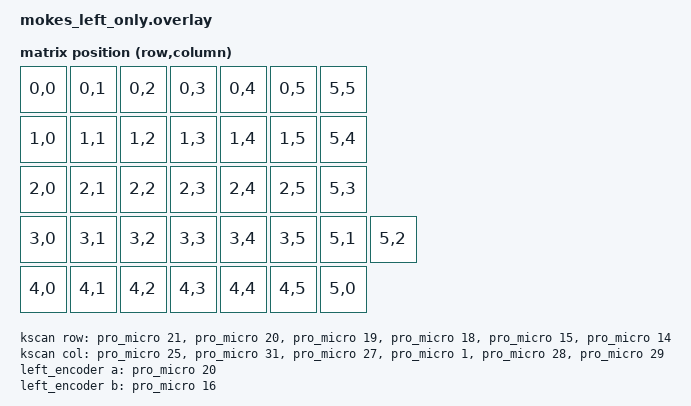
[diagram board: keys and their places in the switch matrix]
// This file was generated from a template. Edit it to match your keyboard.
// See https://zmk.dev/docs/development/hardware-integration/new-shield for more
// instructions.

#include <dt-bindings/zmk/matrix_transform.h>

#include "mokes_left_only-layouts.dtsi"

/ {
    chosen {
        zmk,physical-layout = &default_layout;
    };

    kscan: kscan {
        // If the hardware does not use a switch matrix, change this to the
        // appropriate driver and update the properties below to match.
        // See https://zmk.dev/docs/config/kscan for supported key scan drivers.
        compatible = "zmk,kscan-gpio-matrix";
        // Set this to "col2row" or "row2col" to match the hardware. If using
        // "row2col", change the col-gpios to (GPIO_ACTIVE_HIGH | GPIO_PULL_DOWN)
        // and the row-gpios to GPIO_ACTIVE_HIGH.
        diode-direction = "col2row";
        wakeup-source;

        // Replace these comments with the GPIO pins in the matrix.
        // See https://zmk.dev/docs/development/hardware-integration/new-shield#shield-overlays
        row-gpios
            = <&pro_micro 21 GPIO_ACTIVE_HIGH>
            , <&pro_micro 20 GPIO_ACTIVE_HIGH>
            , <&pro_micro 19 GPIO_ACTIVE_HIGH>
            , <&pro_micro 18 GPIO_ACTIVE_HIGH>
            , <&pro_micro 15 GPIO_ACTIVE_HIGH>
            , <&pro_micro 14 GPIO_ACTIVE_HIGH>
            ;
        col-gpios
            = <&pro_micro 25 (GPIO_ACTIVE_HIGH | GPIO_PULL_DOWN)>
            , <&pro_micro 31 (GPIO_ACTIVE_HIGH | GPIO_PULL_DOWN)>
            , <&pro_micro 27 (GPIO_ACTIVE_HIGH | GPIO_PULL_DOWN)>
            , <&pro_micro 1 (GPIO_ACTIVE_HIGH | GPIO_PULL_DOWN)>
            , <&pro_micro 28 (GPIO_ACTIVE_HIGH | GPIO_PULL_DOWN)>
            , <&pro_micro 29 (GPIO_ACTIVE_HIGH | GPIO_PULL_DOWN)>
            ;
    };
    
    left_encoder: encoder_left {
        compatible = "alps,ec11";
        a-gpios = <&pro_micro 20 (GPIO_ACTIVE_HIGH | GPIO_PULL_UP)>;
        b-gpios = <&pro_micro 16 (GPIO_ACTIVE_HIGH | GPIO_PULL_UP)>;
        steps = <80>;
        status = "disabled";
    };


//Key matrix pins
//define MATRIX_ROW_PINS { F4, F5, F6, F7, B1, B3 }
//                         21, 20, 19, 18, 15, 14
//define MATRIX_COL_PINS { D4, C6, D7, E6, B4, B5 }
//                         25, 31, 27, 1,  28, 29
//Encoder pins
//define ENCODERS_PAD_A { D2 }
//define ENCODERS_PAD_B { B2 }
// RGB_DI_PIN B6
// L00, L01, L02, L03, L04, L05, L06,    
// L10, L11, L12, L13, L14, L15, L16,    
// L20, L21, L22, L23, L24, L25, L26,    
// L30, L31, L32, L33, L34, L35, L36, L37
// L40, L41, L42, L43,    L44, L45,   L46
// { L00, L01, L02, L03, L04, L05 }, \
// { L10, L11, L12, L13, L14, L15 }, \
// { L20, L21, L22, L23, L24, L25 }, \
// { L30, L31, L32, L33, L34, L35 }, \
// { L40, L41, L42, L43, L44, L45 }, \
// { L46, L36, L37, L26, L16, L06 }, \



    default_transform: default_transform {
        // See https://zmk.dev/docs/development/hardware-integration/new-shield#matrix-transform
        // for how to configure this
        compatible = "zmk,matrix-transform";
        columns = <6>;
        rows = <6>;

        map = <
            RC(0, 0) RC(0, 1) RC(0, 2) RC(0, 3) RC(0, 4) RC(0, 5) RC(5, 5) 
            RC(1, 0) RC(1, 1) RC(1, 2) RC(1, 3) RC(1, 4) RC(1, 5) RC(5, 4)
            RC(2, 0) RC(2, 1) RC(2, 2) RC(2, 3) RC(2, 4) RC(2, 5) RC(5, 3)
            RC(3, 0) RC(3, 1) RC(3, 2) RC(3, 3) RC(3, 4) RC(3, 5) RC(5, 1) RC(5, 2)
            RC(4, 0) RC(4, 1) RC(4, 2) RC(4, 3) RC(4, 4) RC(4, 5) RC(5, 0)
        >;
    };
};


&pro_micro_i2c {
    status = "okay";

    oled: ssd1306@3c {
        compatible = "solomon,ssd1306fb";
        reg = <0x3c>;
        label = "DISPLAY";
        width = <128>;
        height = <32>;
        segment-offset = <0>;
        page-offset = <0>;
        display-offset = <0>;
        multiplex-ratio = <31>;
        segment-remap;
        com-invdir;
        com-sequential;
        prechargep = <0x22>;
    };
};
